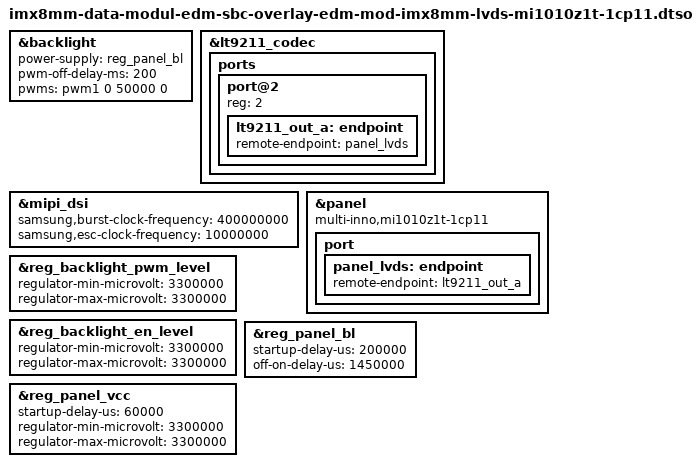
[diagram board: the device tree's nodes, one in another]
// SPDX-License-Identifier: (GPL-2.0+ OR MIT)
/*
 * Copyright 2024-2026 Marek Vasut
 */

#include "imx8mm-data-modul-edm-sbc-overlay-edm-mod-imx8mm-lvds.dtsi"

&backlight {
	power-supply = <&reg_panel_bl>;
	/* 3 POWER ON/OFF SEQUENCE, T7 >= 200 ms */
	pwm-off-delay-ms = <200>;
	/* ELECTRICAL CHARACTERISTICS, BL_ADJ Frequency 20K HZ Typ., value below in ns */
	pwms = <&pwm1 0 50000 0>;
	status = "okay";
};

&lt9211_codec {
	ports {
		port@2 {
			reg = <2>;

			lt9211_out_a: endpoint {
				remote-endpoint = <&panel_lvds>;
			};
		};
	};
};

&mipi_dsi {
	samsung,burst-clock-frequency = <400000000>;
	samsung,esc-clock-frequency = <10000000>;
};

&panel {
	compatible = "multi-inno,mi1010z1t-1cp11";
	status = "okay";

	port {
		panel_lvds: endpoint {
			remote-endpoint = <&lt9211_out_a>;
		};
	};
};

&reg_backlight_pwm_level {
	/* Always only output 3.3V on this MI1010Z1T-1CP11 panel unit. */
	regulator-min-microvolt = <3300000>;
	regulator-max-microvolt = <3300000>;
};

&reg_backlight_en_level {
	/* Always only output 3.3V on this MI1010Z1T-1CP11 panel unit. */
	regulator-min-microvolt = <3300000>;
	regulator-max-microvolt = <3300000>;
};

&reg_panel_bl {
	startup-delay-us = <200000>; /* T6 */
	off-on-delay-us = <1450000>; /* T7 + T3 + T4 + T5 + T1 + T2 + T6 */
	status = "okay";
};

&reg_panel_vcc {
	/* 3 POWER ON/OFF SEQUENCE */
	startup-delay-us = <60000>; /* T1 + T2 >= 1 ms (typ. 60ms) */

	/* Always only output 3.3V on this MI1010Z1T-1CP11 panel unit. */
	regulator-min-microvolt = <3300000>;
	regulator-max-microvolt = <3300000>;
};
